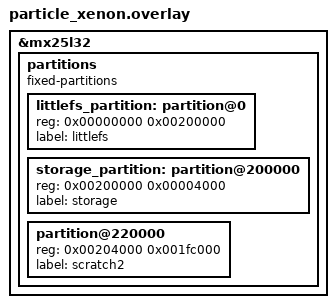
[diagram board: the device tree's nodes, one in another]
/*
 * Copyright (c) 2019 Peter Bigot Consulting, LLC
 *
 * SPDX-License-Identifier: Apache-2.0
 */

/delete-node/ &storage_partition;

&mx25l32 {
	partitions {
		compatible = "fixed-partitions";
		#address-cells = <1>;
		#size-cells = <1>;

		littlefs_partition: partition@0 {
			reg = <0x00000000 0x00200000>;
			label = "littlefs";
		};

		storage_partition: partition@200000 {
			reg = <0x00200000 0x00004000>;
			label = "storage";
		};

		partition@220000 {
			reg = <0x00204000 0x001fc000>;
			label = "scratch2";
		};
	};
};
